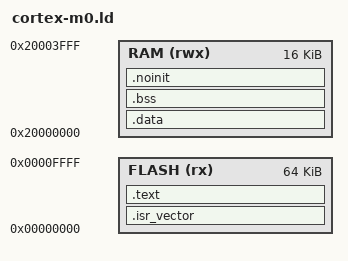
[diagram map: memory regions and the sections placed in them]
ENTRY(_start)

MEMORY
{
    FLASH (rx)  : ORIGIN = 0x00000000, LENGTH = 64K
    RAM   (rwx) : ORIGIN = 0x20000000, LENGTH = 16K
}

SECTIONS
{
    .isr_vector :
    {
        . = ALIGN(4);
        KEEP(*(.isr_vector))
        . = ALIGN(4);
    } > FLASH

    .text :
    {
        . = ALIGN(4);
        *(.text*)
        *(.rodata*)
        *(.glue_7)
        *(.glue_7t)
        . = ALIGN(4);
        _etext = .;
    } > FLASH

    .data : AT(_etext)
    {
        . = ALIGN(4);
        _sdata = .;
        *(.data*)
        . = ALIGN(4);
        _edata = .;
    } > RAM

    .bss (NOLOAD) :
    {
        . = ALIGN(4);
        _sbss = .;
        *(.bss*)
        *(COMMON)
        . = ALIGN(4);
        _ebss = .;
    } > RAM

    .noinit (NOLOAD) :
    {
        . = ALIGN(4);
        *(.noinit*)
        . = ALIGN(4);
    } > RAM

    /DISCARD/ :
    {
        *(.comment)
        *(.note*)
        *(.eh_frame*)
    }

    _end = .;
}

ASSERT(SIZEOF(.text) + SIZEOF(.isr_vector) + SIZEOF(.data) <= LENGTH(FLASH), "FLASH overflow")
ASSERT(SIZEOF(.data) + SIZEOF(.bss) + SIZEOF(.noinit) <= LENGTH(RAM), "RAM overflow")
